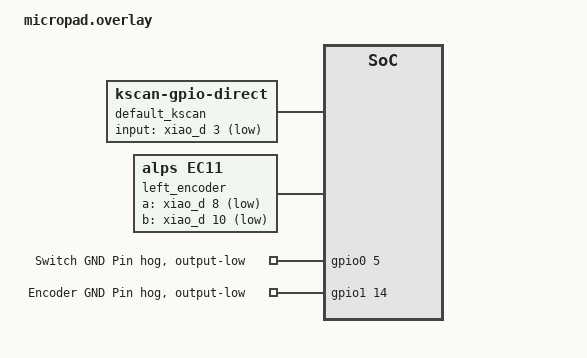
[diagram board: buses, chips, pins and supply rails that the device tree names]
#include <physical_layouts.dtsi>
#include <dt-bindings/zmk/matrix_transform.h>

/ {
    chosen {
        zmk,physical-layout = &layout;
    };

    default_kscan: kscan {
        compatible = "zmk,kscan-gpio-direct";
        wakeup-source;
        input-gpios =
            <&xiao_d 3 (GPIO_ACTIVE_LOW | GPIO_PULL_UP)>;
    };

    left_encoder: encoder_left {
        compatible = "alps,ec11";
        a-gpios = <&xiao_d 8 (GPIO_ACTIVE_LOW | GPIO_PULL_UP)>;
        b-gpios = <&xiao_d 10 (GPIO_ACTIVE_LOW | GPIO_PULL_UP)>;
        steps = <50>;
        status = "okay";
    };

    sensors {
        compatible = "zmk,keymap-sensors";
        sensors = <&left_encoder>;
    };

    transform: matrix_transform {
        compatible = "zmk,matrix-transform";
        rows = <1>;
        columns = <1>;
        map = <
            RC(0, 0)
        >;
    };

    layout: layout {
        compatible = "zmk,physical-layout";
        display-name = "Micropad";
        transform = <&transform>;
        kscan = <&default_kscan>;

        keys  //                     w   h    x    y     rot    rx    ry
            = <&key_physical_attrs 100 100    0    0       0     0     0>;
    };
};

&gpio0 {
    swgnd: switch-gnd-pin {
        gpio-hog;
        gpios = <5 GPIO_ACTIVE_HIGH>;
        output-low;
        line-name = "Switch GND Pin";
    };
};

&gpio1 {
    encgnd: encoder-gnd-pin {
        gpio-hog;
        gpios = <14 GPIO_ACTIVE_HIGH>;
        output-low;
        line-name = "Encoder GND Pin";
    };
};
